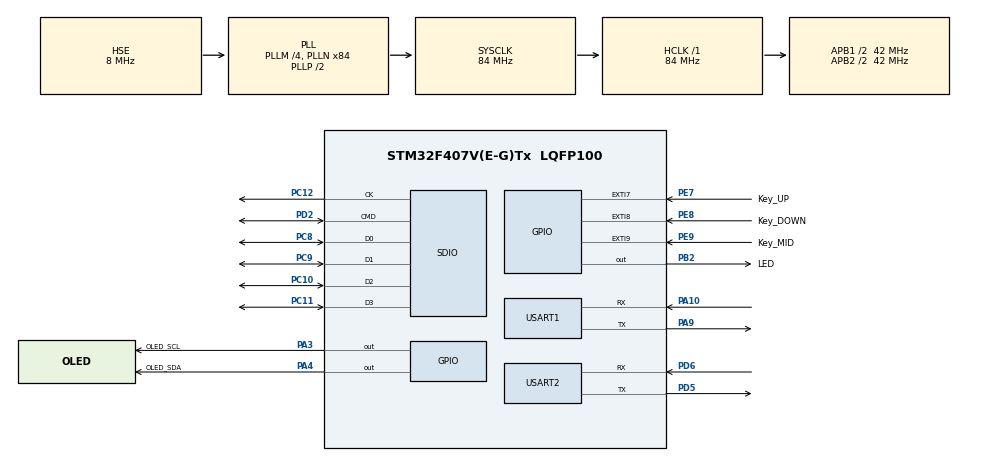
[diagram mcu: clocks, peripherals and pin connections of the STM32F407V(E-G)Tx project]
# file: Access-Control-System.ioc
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Dma.Request0=USART1_RX
Dma.Request1=USART1_TX
Dma.Request2=USART2_RX
Dma.Request3=USART2_TX
Dma.USART1_RX.0.Direction=DMA_PERIPH_TO_MEMORY
Dma.USART1_RX.0.FIFOMode=DMA_FIFOMODE_DISABLE
Dma.USART1_RX.0.Instance=DMA2_Stream2
Dma.USART1_RX.0.MemDataAlignment=DMA_MDATAALIGN_BYTE
Dma.USART1_RX.0.MemInc=DMA_MINC_ENABLE
Dma.USART1_RX.0.Mode=DMA_NORMAL
Dma.USART1_RX.0.PeriphDataAlignment=DMA_PDATAALIGN_BYTE
Dma.USART1_RX.0.PeriphInc=DMA_PINC_DISABLE
Dma.USART1_RX.0.Priority=DMA_PRIORITY_VERY_HIGH
Dma.USART1_TX.1.Direction=DMA_MEMORY_TO_PERIPH
Dma.USART1_TX.1.FIFOMode=DMA_FIFOMODE_DISABLE
Dma.USART1_TX.1.Instance=DMA2_Stream7
Dma.USART1_TX.1.MemDataAlignment=DMA_MDATAALIGN_BYTE
Dma.USART1_TX.1.MemInc=DMA_MINC_ENABLE
Dma.USART1_TX.1.Mode=DMA_NORMAL
Dma.USART1_TX.1.PeriphDataAlignment=DMA_PDATAALIGN_BYTE
Dma.USART1_TX.1.PeriphInc=DMA_PINC_DISABLE
Dma.USART1_TX.1.Priority=DMA_PRIORITY_VERY_HIGH
Dma.USART2_RX.2.Direction=DMA_PERIPH_TO_MEMORY
Dma.USART2_RX.2.FIFOMode=DMA_FIFOMODE_DISABLE
Dma.USART2_RX.2.Instance=DMA1_Stream5
Dma.USART2_RX.2.MemDataAlignment=DMA_MDATAALIGN_BYTE
Dma.USART2_RX.2.MemInc=DMA_MINC_ENABLE
Dma.USART2_RX.2.Mode=DMA_NORMAL
Dma.USART2_RX.2.PeriphDataAlignment=DMA_PDATAALIGN_BYTE
Dma.USART2_RX.2.PeriphInc=DMA_PINC_DISABLE
Dma.USART2_RX.2.Priority=DMA_PRIORITY_VERY_HIGH
Dma.USART2_TX.3.Direction=DMA_MEMORY_TO_PERIPH
Dma.USART2_TX.3.FIFOMode=DMA_FIFOMODE_DISABLE
Dma.USART2_TX.3.Instance=DMA1_Stream6
Dma.USART2_TX.3.MemDataAlignment=DMA_MDATAALIGN_BYTE
Dma.USART2_TX.3.MemInc=DMA_MINC_ENABLE
Dma.USART2_TX.3.Mode=DMA_NORMAL
Dma.USART2_TX.3.PeriphDataAlignment=DMA_PDATAALIGN_BYTE
Dma.USART2_TX.3.PeriphInc=DMA_PINC_DISABLE
Dma.USART2_TX.3.Priority=DMA_PRIORITY_VERY_HIGH
FATFS._CODE_PAGE=936
FATFS._MAX_LFN=32
FATFS._USE_FIND=1
FATFS._USE_LFN=2
Mcu.Family=STM32F4
Mcu.Name=STM32F407V(E-G)Tx
Mcu.Package=LQFP100
NVIC.DMA1_Stream5_IRQn=true\:1\:0\:true\:false\:true\:false\:true\:true
NVIC.DMA1_Stream6_IRQn=true\:1\:0\:true\:false\:true\:false\:true\:true
NVIC.DMA2_Stream2_IRQn=true\:1\:0\:true\:false\:true\:false\:true\:true
NVIC.DMA2_Stream7_IRQn=true\:1\:0\:true\:false\:true\:false\:true\:true
NVIC.EXTI9_5_IRQn=true\:5\:0\:true\:false\:true\:true\:true\:true
NVIC.PriorityGroup=NVIC_PRIORITYGROUP_4
NVIC.SDIO_IRQn=true\:0\:0\:true\:false\:true\:true\:true\:true
NVIC.TIM2_IRQn=true\:4\:0\:true\:false\:true\:true\:true\:true
NVIC.USART1_IRQn=true\:1\:0\:true\:false\:true\:true\:true\:true
NVIC.USART2_IRQn=true\:1\:0\:true\:false\:true\:true\:true\:true
PA10.Mode=Asynchronous
PA10.Signal=USART1_RX
PA13.Mode=Serial_Wire
PA13.Signal=SYS_JTMS-SWDIO
PA14.Mode=Serial_Wire
PA14.Signal=SYS_JTCK-SWCLK
PA3.GPIO_Label=OLED_SCL
PA3.GPIO_ModeDefaultOutputPP=GPIO_MODE_OUTPUT_OD
PA3.GPIO_PuPd=GPIO_PULLUP
PA3.PinState=GPIO_PIN_SET
PA3.Signal=GPIO_Output
PA4.GPIO_Label=OLED_SDA
PA4.GPIO_ModeDefaultOutputPP=GPIO_MODE_OUTPUT_OD
PA4.GPIO_PuPd=GPIO_PULLUP
PA4.PinState=GPIO_PIN_SET
PA4.Signal=GPIO_Output
PA9.Mode=Asynchronous
PA9.Signal=USART1_TX
PB2.GPIO_Label=LED
PB2.Signal=GPIO_Output
PC10.Mode=SD_4_bits_Wide_bus
PC10.Signal=SDIO_D2
PC11.Mode=SD_4_bits_Wide_bus
PC11.Signal=SDIO_D3
PC12.Mode=SD_4_bits_Wide_bus
PC12.Signal=SDIO_CK
PC8.Mode=SD_4_bits_Wide_bus
PC8.Signal=SDIO_D0
PC9.Mode=SD_4_bits_Wide_bus
PC9.Signal=SDIO_D1
PD2.Mode=SD_4_bits_Wide_bus
PD2.Signal=SDIO_CMD
PD5.Mode=Asynchronous
PD5.Signal=USART2_TX
PD6.Mode=Asynchronous
PD6.Signal=USART2_RX
PE7.GPIO_Label=Key_UP
PE7.GPIO_ModeDefaultEXTI=GPIO_MODE_IT_FALLING
PE7.GPIO_PuPd=GPIO_PULLUP
PE7.Signal=GPXTI7
PE8.GPIO_Label=Key_DOWN
PE8.GPIO_ModeDefaultEXTI=GPIO_MODE_IT_FALLING
PE8.GPIO_PuPd=GPIO_PULLUP
PE8.Signal=GPXTI8
PE9.GPIO_Label=Key_MID
PE9.GPIO_ModeDefaultEXTI=GPIO_MODE_IT_FALLING
PE9.GPIO_PuPd=GPIO_PULLUP
PE9.Signal=GPXTI9
PH0-OSC_IN.Mode=HSE-External-Oscillator
PH0-OSC_IN.Signal=RCC_OSC_IN
PH1-OSC_OUT.Mode=HSE-External-Oscillator
PH1-OSC_OUT.Signal=RCC_OSC_OUT
ProjectManager.HeapSize=0x200
ProjectManager.StackSize=0x1000
ProjectManager.TargetToolchain=MDK-ARM V5.32
RCC.48MHZClocksFreq_Value=42000000
RCC.AHBFreq_Value=84000000
RCC.APB1CLKDivider=RCC_HCLK_DIV2
RCC.APB1Freq_Value=42000000
RCC.APB1TimFreq_Value=84000000
RCC.APB2CLKDivider=RCC_HCLK_DIV2
RCC.APB2Freq_Value=42000000
RCC.APB2TimFreq_Value=84000000
RCC.CortexFreq_Value=84000000
RCC.HCLKFreq_Value=84000000
RCC.HSE_VALUE=8000000
RCC.HSI_VALUE=16000000
RCC.LSE_VALUE=32768
RCC.PLLM=4
RCC.PLLN=84
RCC.PLLSourceVirtual=RCC_PLLSOURCE_HSE
RCC.SYSCLKFreq_VALUE=84000000
RCC.SYSCLKSource=RCC_SYSCLKSOURCE_PLLCLK
RCC.VCOOutputFreq_Value=168000000
SDIO.ClockDiv=34
TIM2.Period=4199
TIM2.Prescaler=199
USART1.VirtualMode=VM_ASYNC
USART2.VirtualMode=VM_ASYNC
VP_FATFS_VS_SDIO.Mode=SDIO
VP_TIM2_VS_ClockSourceINT.Mode=Internal
board=custom

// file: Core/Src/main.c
/* USER CODE BEGIN Header */
/**
  ******************************************************************************
  * @file           :  Access-Control-System
  *
  * @author         :  ljc
  *
  * @date           :  2025.3.9
  *
  * @platform       :  STM32F407VET6
  ******************************************************************************
  */

/* USER CODE END Header */
#include "main.h"
#include "dma.h"
#include "fatfs.h"
#include "sdio.h"
#include "tim.h"
#include "usart.h"
#include "gpio.h"

/* USER CODE BEGIN Includes */
#include "Menu_app.h"
#include "Esp8266.h"
#include "protocol.h"
/* USER CODE END Includes */

void SystemClock_Config(void);

int main(void)
{

  /* MCU Configuration--------------------------------------------------------*/

  /* Reset of all peripherals, Initializes the Flash interface and the Systick. */
  HAL_Init();

  /* Configure the system clock */
  SystemClock_Config();

  /* Initialize all configured peripherals */
  MX_GPIO_Init();
  MX_DMA_Init();
  MX_SDIO_SD_Init();
  MX_FATFS_Init();
  MX_TIM2_Init();
  MX_USART1_UART_Init();
  MX_USART2_UART_Init();
  /* USER CODE BEGIN 2 */
  my_uart_init();
  Esp_Init();
  SD_load();
  Menu_Init();
  /* USER CODE END 2 */

  /* Infinite loop */
  /* USER CODE BEGIN WHILE */
  //加入加载完成标识，如屏幕显示开机logo，等待确认后进入
  while (1)
  {
      Menu_Choose();
      Esp_Set_Reply();
    /* USER CODE END WHILE */

  }
}

void SystemClock_Config(void)
{
  RCC_OscInitTypeDef RCC_OscInitStruct = {0};
  RCC_ClkInitTypeDef RCC_ClkInitStruct = {0};

  /** Configure the main internal regulator output voltage
  */
  __HAL_RCC_PWR_CLK_ENABLE();
  __HAL_PWR_VOLTAGESCALING_CONFIG(PWR_REGULATOR_VOLTAGE_SCALE1);

  /** Initializes the RCC Oscillators according to the specified parameters
  * in the RCC_OscInitTypeDef structure.
  */
  RCC_OscInitStruct.OscillatorType = RCC_OSCILLATORTYPE_HSE;
  RCC_OscInitStruct.HSEState = RCC_HSE_ON;
  RCC_OscInitStruct.PLL.PLLState = RCC_PLL_ON;
  RCC_OscInitStruct.PLL.PLLSource = RCC_PLLSOURCE_HSE;
  RCC_OscInitStruct.PLL.PLLM = 4;
  RCC_OscInitStruct.PLL.PLLN = 84;
  RCC_OscInitStruct.PLL.PLLP = RCC_PLLP_DIV2;
  RCC_OscInitStruct.PLL.PLLQ = 4;
  if (HAL_RCC_OscConfig(&RCC_OscInitStruct) != HAL_OK)
  {
    Error_Handler();
  }

  /** Initializes the CPU, AHB and APB buses clocks
  */
  RCC_ClkInitStruct.ClockType = RCC_CLOCKTYPE_HCLK|RCC_CLOCKTYPE_SYSCLK
                              |RCC_CLOCKTYPE_PCLK1|RCC_CLOCKTYPE_PCLK2;
  RCC_ClkInitStruct.SYSCLKSource = RCC_SYSCLKSOURCE_PLLCLK;
  RCC_ClkInitStruct.AHBCLKDivider = RCC_SYSCLK_DIV1;
  RCC_ClkInitStruct.APB1CLKDivider = RCC_HCLK_DIV2;
  RCC_ClkInitStruct.APB2CLKDivider = RCC_HCLK_DIV2;

  if (HAL_RCC_ClockConfig(&RCC_ClkInitStruct, FLASH_LATENCY_2) != HAL_OK)
  {
    Error_Handler();
  }
}

void Error_Handler(void)
{
  __disable_irq();
  while (1)
  {
  }
}
